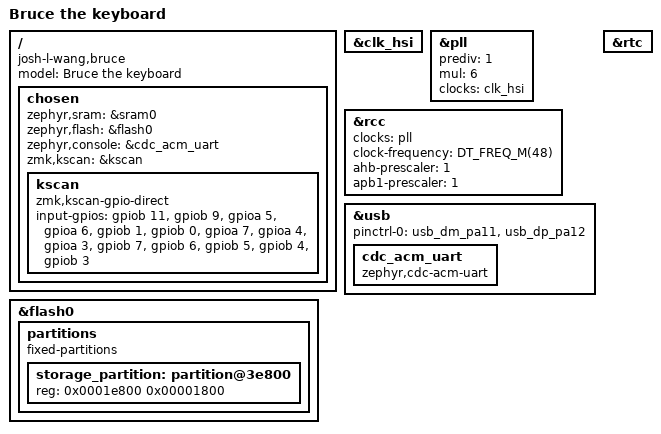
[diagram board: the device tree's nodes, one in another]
/*
 * Copyright (c) 2024 The ZMK Contributors
 *
 * SPDX-License-Identifier: MIT
 */

/dts-v1/;
#include <st/f0/stm32f072Xb.dtsi>
#include <st/f0/stm32f072c(8-b)tx-pinctrl.dtsi>

/ {
    model = "Bruce the keyboard";
    compatible = "josh-l-wang,bruce", "st,stm32f072";

    chosen {
        zephyr,sram = &sram0;
        zephyr,flash = &flash0;
        zephyr,console = &cdc_acm_uart;

        zmk,kscan = &kscan;

    kscan: kscan {
        compatible = "zmk,kscan-gpio-direct";

        input-gpios
            = <&gpiob 11 (GPIO_ACTIVE_HIGH | GPIO_PULL_DOWN)>
            , <&gpiob 9 (GPIO_ACTIVE_HIGH | GPIO_PULL_DOWN)>
            , <&gpioa 5 (GPIO_ACTIVE_HIGH | GPIO_PULL_DOWN)>
            , <&gpioa 6 (GPIO_ACTIVE_HIGH | GPIO_PULL_DOWN)>
            , <&gpiob 1 GPIO_ACTIVE_HIGH>
            , <&gpiob 0 GPIO_ACTIVE_HIGH>
            , <&gpioa 7 GPIO_ACTIVE_HIGH>
            , <&gpioa 4 GPIO_ACTIVE_HIGH>
            , <&gpioa 3 GPIO_ACTIVE_HIGH>
            , <&gpiob 7 GPIO_ACTIVE_HIGH>
            , <&gpiob 6 GPIO_ACTIVE_HIGH>
            , <&gpiob 5 GPIO_ACTIVE_HIGH>
            , <&gpiob 4 GPIO_ACTIVE_HIGH>
            , <&gpiob 3 GPIO_ACTIVE_HIGH>
            ;
        };

    };

};

&clk_hsi {
    status = "okay";
};

&pll {
    status = "okay";
    prediv = <1>;
    mul = <6>;
    clocks = <&clk_hsi>;
};

&rcc {
    clocks = <&pll>;
    clock-frequency = <DT_FREQ_M(48)>;
    ahb-prescaler = <1>;
    apb1-prescaler = <1>;
};

&usb {
    status = "okay";
    pinctrl-0 = <&usb_dm_pa11 &usb_dp_pa12>;
    pinctrl-names = "default";
    cdc_acm_uart: cdc_acm_uart {
        compatible = "zephyr,cdc-acm-uart";
    };
};

&rtc {
    status = "okay";
};

&flash0 {
    /*
     * For more information, see:
     * http://docs.zephyrproject.org/latest/guides/dts/index.html#flash-partitions
     */
    partitions {
        compatible = "fixed-partitions";
        #address-cells = <1>;
        #size-cells = <1>;

        /* Set 6Kb of storage at the end of the 128Kb of flash */
        storage_partition: partition@3e800 {
            reg = <0x0001e800 0x00001800>;
        };
    };
};

